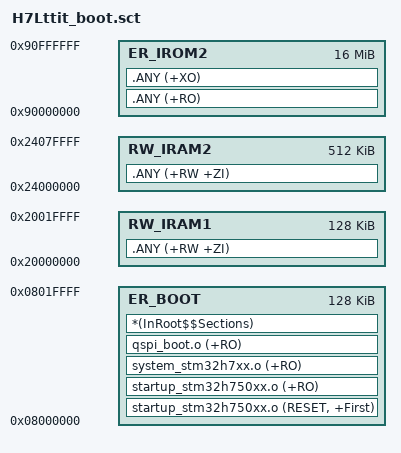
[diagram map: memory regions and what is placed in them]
LR_BOOT 0x08000000 0x00020000  {
  ER_BOOT 0x08000000 0x00020000  {
   startup_stm32h750xx.o (RESET, +First)
   startup_stm32h750xx.o (+RO)
   system_stm32h7xx.o (+RO)
   qspi_boot.o (+RO)
   *(InRoot$$Sections)
  }
  RW_IRAM1 0x20000000 0x00020000  {
   .ANY (+RW +ZI)
  }
  RW_IRAM2 0x24000000 0x00080000  {
   .ANY (+RW +ZI)
  }
}

LR_IROM2 0x90000000 0x01000000  {
  ER_IROM2 0x90000000 0x01000000  {
   .ANY (+RO)
   .ANY (+XO)
  }
}
